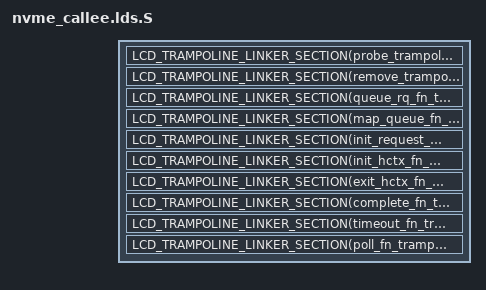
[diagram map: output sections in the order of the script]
#include <liblcd/trampoline_link.h>

SECTIONS
{
	LCD_TRAMPOLINE_LINKER_SECTION(probe_trampoline)
	LCD_TRAMPOLINE_LINKER_SECTION(remove_trampoline)
	LCD_TRAMPOLINE_LINKER_SECTION(queue_rq_fn_trampoline)
	LCD_TRAMPOLINE_LINKER_SECTION(map_queue_fn_trampoline)
	LCD_TRAMPOLINE_LINKER_SECTION(init_request_fn_trampoline)
	LCD_TRAMPOLINE_LINKER_SECTION(init_hctx_fn_trampoline)
	LCD_TRAMPOLINE_LINKER_SECTION(exit_hctx_fn_trampoline)
	LCD_TRAMPOLINE_LINKER_SECTION(complete_fn_trampoline)
	LCD_TRAMPOLINE_LINKER_SECTION(timeout_fn_trampoline)
	LCD_TRAMPOLINE_LINKER_SECTION(poll_fn_trampoline)
}
INSERT AFTER .text;
